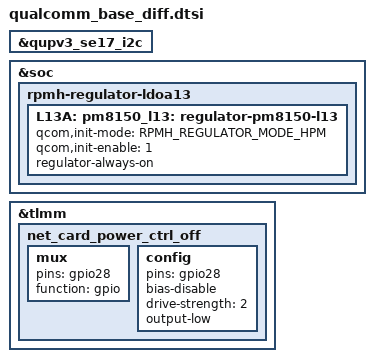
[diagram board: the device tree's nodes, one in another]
/*
 * this file is ued to change qualcomm dtsi which can't be changed by overlay
 * such as /delete-node/ /delete-property/ and alises
 * other changes must set in overlay dtsi files
 */
&qupv3_se17_i2c {
	/delete-node/ himax-ts@48;
};

&soc {
	rpmh-regulator-ldoa13 {
		L13A: pm8150_l13: regulator-pm8150-l13 {
			qcom,init-mode = <RPMH_REGULATOR_MODE_HPM>;
			qcom,init-enable = <1>;
			regulator-always-on;
		};
	};
};

&tlmm {
	net_card_power_ctrl_off: net_card_power_ctrl_off {
		mux {
			pins = "gpio28";
			function = "gpio";
		};

		config {
			pins = "gpio28";
			bias-disable;           /* NO pull */
			drive-strength = <2>;   /* 2 MA */
			output-low;
		};
	};
};

